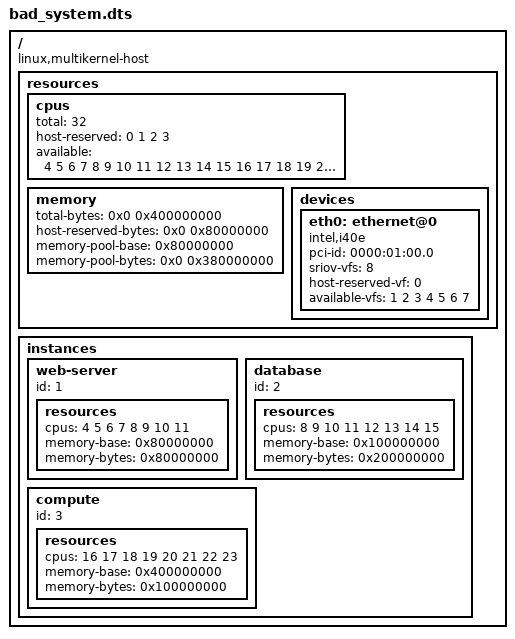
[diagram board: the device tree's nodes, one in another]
/multikernel-v1/;

/ {
    compatible = "linux,multikernel-host";
    
    resources {
        cpus {
            total = <32>;
            host-reserved = <0 1 2 3>;
            available = <4 5 6 7 8 9 10 11 12 13 14 15 
                        16 17 18 19 20 21 22 23 24 25 26 27 28 29 30 31>;
        };
        
        memory {
            total-bytes = <0x0 0x400000000>;      // 16GB
            host-reserved-bytes = <0x0 0x80000000>; // 2GB
            memory-pool-base = <0x80000000>;
            memory-pool-bytes = <0x0 0x380000000>;  // 14GB
        };
        
        devices {
            eth0: ethernet@0 {
                compatible = "intel,i40e";
                pci-id = "0000:01:00.0";
                sriov-vfs = <8>;
                host-reserved-vf = <0>;
                available-vfs = <1 2 3 4 5 6 7>;
            };
        };
    };
    
    instances {
        // This will cause CPU overlap with database
        web-server {
            id = <1>;
            resources {
                cpus = <4 5 6 7 8 9 10 11>;  // Overlaps with database
                memory-base = <0x80000000>;
                memory-bytes = <0x80000000>;  // 2GB
            };
        };
        
        // This will cause CPU overlap with web-server
        database {
            id = <2>;
            resources {
                cpus = <8 9 10 11 12 13 14 15>;  // Overlaps with web-server
                memory-base = <0x100000000>;
                memory-bytes = <0x200000000>;  // 8GB
            };
        };
        
        // This will cause memory overflow
        compute {
            id = <3>;
            resources {
                cpus = <16 17 18 19 20 21 22 23>;
                memory-base = <0x400000000>;  // Beyond memory pool
                memory-bytes = <0x100000000>;  // 4GB
            };
        };
    };
};
